# STM32G474xx register map
File version: 1.5
CPU: CM4 r0p1, little endian, MPU, FPU, 4 interrupt priority bits
Registers are 32-bit, read-write, reset 0x0 unless marked. A register's access mark holds for its fields unless they carry their own. Offsets are from the block's base; [hi:lo] are bit positions; {n}, {i} and the like mark numbered series.

## TIM6 — Basic-timers
Base 0x40001000
Same registers: TIM7 0x40001400
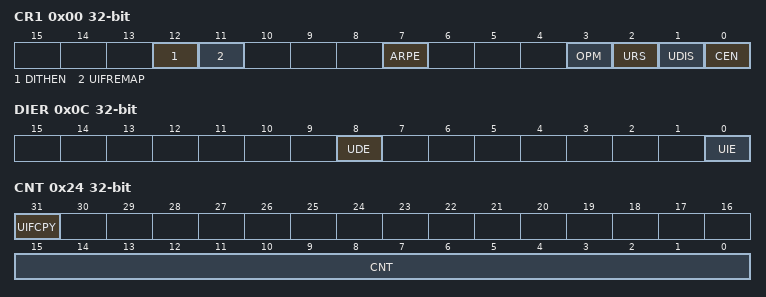
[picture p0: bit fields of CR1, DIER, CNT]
0x00 CR1 — control register 1
  [12] DITHEN — Dithering Enable
  [11] UIFREMAP — UIF status bit remapping
  [7] ARPE — Auto-reload preload enable
  [3] OPM — One-pulse mode
  [2] URS — Update request source
  [1] UDIS — Update disable
  [0] CEN — Counter enable
0x04 CR2 — control register 2
  [6:4] MMS — Master mode selection
0x0C DIER — DMA/Interrupt enable register
  [8] UDE — Update DMA request enable
  [0] UIE — Update interrupt enable
0x10 SR — status register
  [0] UIF — Update interrupt flag
0x14 EGR wo — event generation register
  [0] UG — Update generation
0x24 CNT access per field — counter
  [31] UIFCPY ro — UIF Copy
  [15:0] CNT rw — Low counter value
0x28 PSC — prescaler
  [15:0] PSC — Prescaler value
0x2C ARR reset 0xFFFF — auto-reload register
  [15:0] ARR — Low Auto-reload value

## LPTIMER1 — Low power timer
Base 0x40007C00
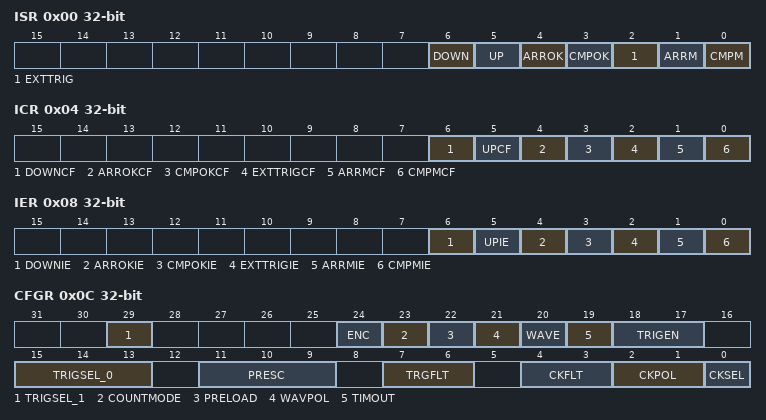
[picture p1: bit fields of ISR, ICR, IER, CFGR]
0x00 ISR ro — Interrupt and Status Register
  [6] DOWN — Counter direction change up to down
  [5] UP — Counter direction change down to up
  [4] ARROK — Autoreload register update OK
  [3] CMPOK — Compare register update OK
  [2] EXTTRIG — External trigger edge event
  [1] ARRM — Autoreload match
  [0] CMPM — Compare match
0x04 ICR wo — Interrupt Clear Register
  [6] DOWNCF — Direction change to down Clear Flag
  [5] UPCF — Direction change to UP Clear Flag
  [4] ARROKCF — Autoreload register update OK Clear Flag
  [3] CMPOKCF — Compare register update OK Clear Flag
  [2] EXTTRIGCF — External trigger valid edge Clear Flag
  [1] ARRMCF — Autoreload match Clear Flag
  [0] CMPMCF — compare match Clear Flag
0x08 IER — Interrupt Enable Register
  [6] DOWNIE — Direction change to down Interrupt Enable
  [5] UPIE — Direction change to UP Interrupt Enable
  [4] ARROKIE — Autoreload register update OK Interrupt Enable
  [3] CMPOKIE — Compare register update OK Interrupt Enable
  [2] EXTTRIGIE — External trigger valid edge Interrupt Enable
  [1] ARRMIE — Autoreload match Interrupt Enable
  [0] CMPMIE — Compare match Interrupt Enable
0x0C CFGR — Configuration Register
  [29] TRIGSEL_1 — Trigger selector bit 3
  [24] ENC — Encoder mode enable
  [23] COUNTMODE — counter mode enabled
  [22] PRELOAD — Registers update mode
  [21] WAVPOL — Waveform shape polarity
  [20] WAVE — Waveform shape
  [19] TIMOUT — Timeout enable
  [18:17] TRIGEN — Trigger enable and polarity
  [15:13] TRIGSEL_0 — Trigger selector bits 0 to 2
  [11:9] PRESC — Clock prescaler
  [7:6] TRGFLT — Configurable digital filter for trigger
  [4:3] CKFLT — Configurable digital filter for external clock
  [2:1] CKPOL — Clock Polarity
  [0] CKSEL — Clock selector
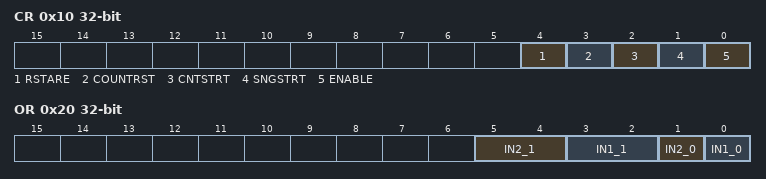
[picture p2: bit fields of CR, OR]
0x10 CR — Control Register
  [4] RSTARE
  [3] COUNTRST
  [2] CNTSTRT — Timer start in continuous mode
  [1] SNGSTRT — LPTIM start in single mode
  [0] ENABLE — LPTIM Enable
0x14 CMP — Compare Register
  [15:0] CMP — Compare value
0x18 ARR reset 0x1 — Autoreload Register
  [15:0] ARR — Auto reload value
0x1C CNT ro — Counter Register
  [15:0] CNT — Counter value
0x20 OR — option register
  [5:4] IN2_1 — IN2 bits 1 to 2
  [3:2] IN1_1 — IN1 bits 1 to 2
  [1] IN2_0 — IN2 bit 0
  [0] IN1_0 — IN1 bit 0

## LPUART1 — Universal synchronous asynchronous receiver transmitter
Base 0x40008000
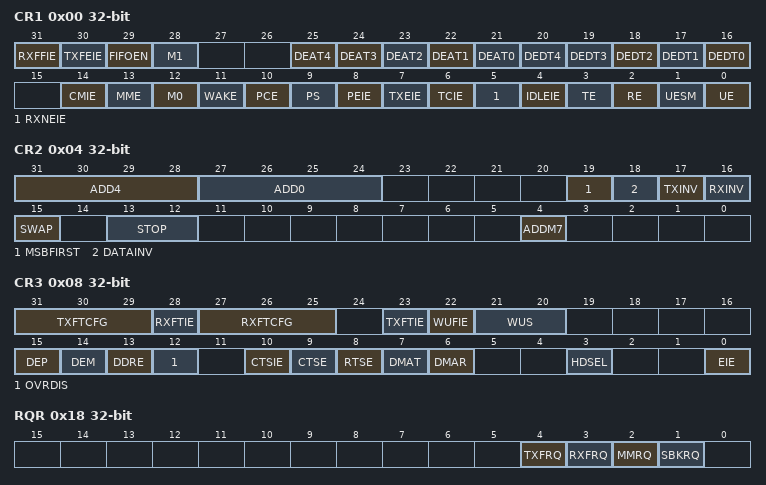
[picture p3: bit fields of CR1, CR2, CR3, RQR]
0x00 CR1 — Control register 1
  [31] RXFFIE
  [30] TXFEIE
  [29] FIFOEN
  [28] M1 — Word length
  [25] DEAT4 — Driver Enable assertion time
  [n+21] DEAT{n} (n=0..3)
  [20] DEDT4 — Driver Enable de-assertion time
  [n+16] DEDT{n} (n=0..3)
  [14] CMIE — Character match interrupt enable
  [13] MME — Mute mode enable
  [12] M0 — Word length
  [11] WAKE — Receiver wakeup method
  [10] PCE — Parity control enable
  [9] PS — Parity selection
  [8] PEIE — PE interrupt enable
  [7] TXEIE — interrupt enable
  [6] TCIE — Transmission complete interrupt enable
  [5] RXNEIE — RXNE interrupt enable
  [4] IDLEIE — IDLE interrupt enable
  [3] TE — Transmitter enable
  [2] RE — Receiver enable
  [1] UESM — USART enable in Stop mode
  [0] UE — USART enable
0x04 CR2 — Control register 2
  [31:28] ADD4 — Address of the USART node
  [27:24] ADD0 — Address of the USART node
  [19] MSBFIRST — Most significant bit first
  [18] DATAINV — Binary data inversion
  [17] TXINV — TX pin active level inversion
  [16] RXINV — RX pin active level inversion
  [15] SWAP — Swap TX/RX pins
  [13:12] STOP — STOP bits
  [4] ADDM7 — 7-bit Address Detection/4-bit Address Detection
0x08 CR3 — Control register 3
  [31:29] TXFTCFG
  [28] RXFTIE
  [27:25] RXFTCFG
  [23] TXFTIE
  [22] WUFIE — Wakeup from Stop mode interrupt enable
  [21:20] WUS — Wakeup from Stop mode interrupt flag selection
  [15] DEP — Driver enable polarity selection
  [14] DEM — Driver enable mode
  [13] DDRE — DMA Disable on Reception Error
  [12] OVRDIS — Overrun Disable
  [10] CTSIE — CTS interrupt enable
  [9] CTSE — CTS enable
  [8] RTSE — RTS enable
  [7] DMAT — DMA enable transmitter
  [6] DMAR — DMA enable receiver
  [3] HDSEL — Half-duplex selection
  [0] EIE — Error interrupt enable
0x0C BRR — Baud rate register
  [19:0] BRR
0x18 RQR wo — Request register
  [4] TXFRQ
  [3] RXFRQ — Receive data flush request
  [2] MMRQ — Mute mode request
  [1] SBKRQ — Send break request
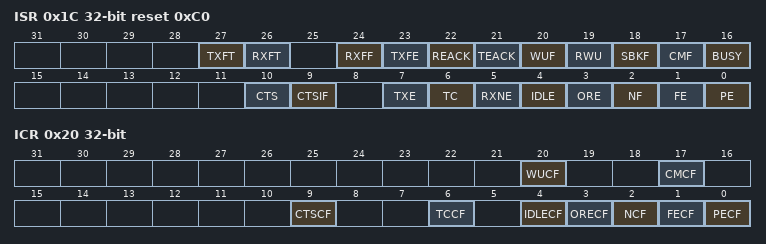
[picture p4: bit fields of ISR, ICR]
0x1C ISR ro reset 0xC0 — Interrupt & status register
  [27] TXFT, [26] RXFT, [24] RXFF, [23] TXFE, [22] REACK, [21] TEACK, [20] WUF, [19] RWU, [18] SBKF, [17] CMF, [16] BUSY, [10] CTS, [9] CTSIF, [7] TXE, [6] TC, [5] RXNE, [4] IDLE, [3] ORE, [2] NF, [1] FE, [0] PE
0x20 ICR wo — Interrupt flag clear register
  [20] WUCF — Wakeup from Stop mode clear flag
  [17] CMCF — Character match clear flag
  [9] CTSCF — CTS clear flag
  [6] TCCF — Transmission complete clear flag
  [4] IDLECF — Idle line detected clear flag
  [3] ORECF — Overrun error clear flag
  [2] NCF — Noise detected clear flag
  [1] FECF — Framing error clear flag
  [0] PECF — Parity error clear flag
0x24 RDR ro — Receive data register
  [8:0] RDR — Receive data value
0x28 TDR — Transmit data register
  [8:0] TDR — Transmit data value
0x2C PRESC — Prescaler register
  [3:0] PRESCALER
